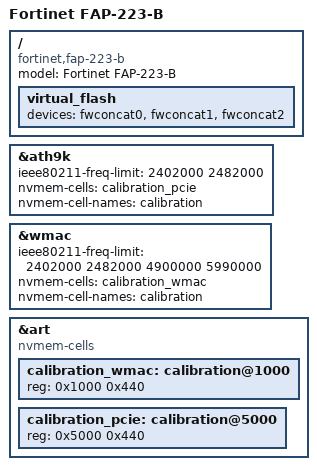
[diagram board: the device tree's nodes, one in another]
// SPDX-License-Identifier: GPL-2.0-or-later OR MIT

#include "ar9344_fortinet_ap-dual.dtsi"

/ {
	compatible = "fortinet,fap-223-b", "qca,ar9344";
	model = "Fortinet FAP-223-B";

	virtual_flash {
		devices = <&fwconcat0 &fwconcat1 &fwconcat2>;
	};
};

&ath9k {
	ieee80211-freq-limit = <2402000 2482000>;

	nvmem-cells = <&calibration_pcie>;
	nvmem-cell-names = "calibration";
};

&wmac {
	ieee80211-freq-limit = <2402000 2482000 4900000 5990000>;

	nvmem-cells = <&calibration_wmac>;
	nvmem-cell-names = "calibration";
};

&art {
	compatible = "nvmem-cells";

	calibration_wmac: calibration@1000 {
		reg = <0x1000 0x440>;
	};

	calibration_pcie: calibration@5000 {
		reg = <0x5000 0x440>;
	};
};
